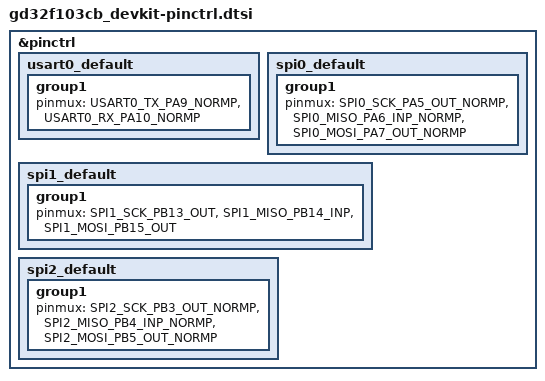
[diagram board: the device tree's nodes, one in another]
/*
 * Copyright (c) 2026
 * SPDX-License-Identifier: Apache-2.0
 *
 * USART0 on PA9/PA10: AFIO map matches GD32E103 medium-density 48-pin
 * (see GigaDevice HAL pinmux tables). Re-check for your PCB.
 */

#include <dt-bindings/pinctrl/gd32e103c(b-8)xx-pinctrl.h>

&pinctrl {
	usart0_default: usart0_default {
		group1 {
			pinmux = <USART0_TX_PA9_NORMP>, <USART0_RX_PA10_NORMP>;
		};
	};

	spi0_default: spi0_default {
		group1 {
			pinmux = <SPI0_SCK_PA5_OUT_NORMP>,
				 <SPI0_MISO_PA6_INP_NORMP>,
				 <SPI0_MOSI_PA7_OUT_NORMP>;
		};
	};

	spi1_default: spi1_default {
		group1 {
			pinmux = <SPI1_SCK_PB13_OUT>,
				 <SPI1_MISO_PB14_INP>,
				 <SPI1_MOSI_PB15_OUT>;
		};
	};

	spi2_default: spi2_default {
		group1 {
			pinmux = <SPI2_SCK_PB3_OUT_NORMP>,
				 <SPI2_MISO_PB4_INP_NORMP>,
				 <SPI2_MOSI_PB5_OUT_NORMP>;
		};
	};
};
